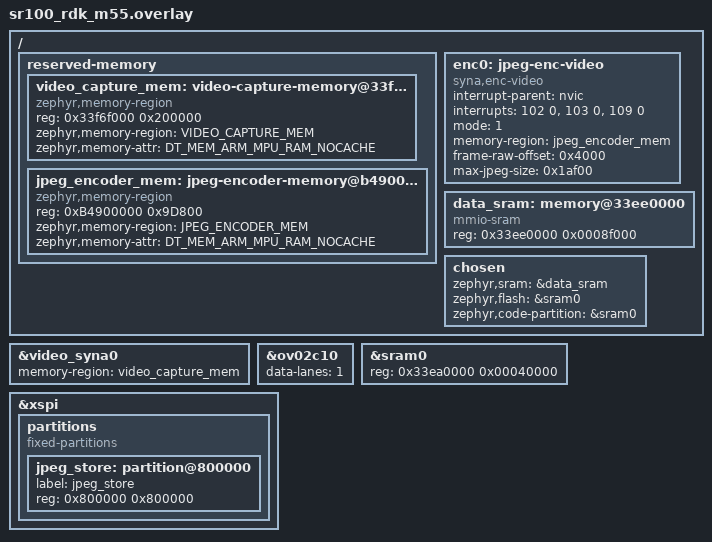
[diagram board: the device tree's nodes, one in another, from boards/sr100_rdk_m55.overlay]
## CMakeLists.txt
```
# Copyright (c) 2026 Synaptics Incorporated
# SPDX-License-Identifier: Apache-2.0

cmake_minimum_required(VERSION 3.20.0)

find_package(Zephyr REQUIRED HINTS $ENV{ZEPHYR_BASE})
project(mipi_capture_to_enc)

if(CONFIG_USB_TRANSPORT_CDC_ACM OR CONFIG_USB_TRANSPORT_UVC)
  include(${ZEPHYR_BASE}/samples/subsys/usb/common/common.cmake)
endif()

target_sources(app PRIVATE src/main.c)

if(CONFIG_USB_TRANSPORT_CDC_ACM)
  target_sources(app PRIVATE src/usb_cdc_transport.c)
endif()

if(CONFIG_USB_TRANSPORT_UVC)
  target_sources(app PRIVATE src/usb_uvc_transport.c)
endif()
```

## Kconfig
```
# Copyright (c) 2026 Synaptics Incorporated
# SPDX-License-Identifier: Apache-2.0

mainmenu "MIPI Capture-to-Encoder Sample"

source "Kconfig.zephyr"

# Tell the SR100 MIPI driver this app provides its own DT-reserved SHM pool
# (video_capture_mem in the board overlay), so the driver's fallback buffer is not
# compiled in.
config VIDEO_SAMPLE_RES_FHD
	bool
	default y

config STORE_TO_XSPI
	bool "Store encoded quadrants to XSPI"
	default n
	select CRC
	select FLASH
	select FLASH_MAP
	select FLASH_PAGE_LAYOUT
	help
	  When enabled, the sample captures one 1080p frame, encodes all four
	  960x540 quadrants one-by-one, and stores each encoded JPEG into the
	  XSPI flash partition labeled "jpeg_store".
	  This partition is optional for USB-only runs (CDC streaming without XSPI).

config USB_TRANSPORT_CDC_ACM
	bool "Enable USB CDC ACM transport"
	default n
	select USB_DEVICE_STACK_NEXT
	select USBD_CDC_ACM_CLASS
	select CRC
	select SERIAL
	select UART_LINE_CTRL
	select UART_INTERRUPT_DRIVEN
	help
	  Enable sending the encoded JPEGs to the host over USB CDC ACM.
	  The device enumerates as a CDC-ACM UART and sends a small binary header
	  followed by the JPEG payload for each quadrant.

config USB_TRANSPORT_UVC
	bool "Enable USB video (UVC) transport"
	default n
	select USB_DEVICE_STACK_NEXT
	select USBD_VIDEO_CLASS
	help
	  Enable streaming the encoded quadrant JPEGs to the host as a USB
	  Video Class (UVC) MJPEG stream.

if USB_TRANSPORT_CDC_ACM || USB_TRANSPORT_UVC
	source "samples/subsys/usb/common/Kconfig.sample_usbd"

config SAMPLE_USBD_PRODUCT
	default "Syna_USB"

config SAMPLE_USBD_PID
	default 0x0008
endif
```

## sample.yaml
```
sample:
  name: mipi_capture_to_enc

tests:
  sample.video.mipi_capture_to_enc:
    tags:
      - video
      - camera
      - jpeg
      - mipi
    integration_platforms:
      - sr100_rdk/sr100/m55

  sample.video.mipi_capture_to_enc.cdc:
    tags:
      - video
      - usb
    integration_platforms:
      - sr100_rdk/sr100/m55
    extra_conf_files:
      - prj_cdc.conf
```

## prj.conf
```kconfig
CONFIG_PRINTK=y
CONFIG_CONSOLE=y
CONFIG_UART_CONSOLE=y
CONFIG_STDOUT_CONSOLE=y

CONFIG_LOG=y
CONFIG_LOG_DEFAULT_LEVEL=3
 
CONFIG_POLL=y

CONFIG_VIDEO=y
CONFIG_VIDEO_SYNA_MIPI=y
CONFIG_VIDEO_SYNA_ENC=y
CONFIG_VIDEO_INIT_PRIORITY=90
CONFIG_VIDEO_SYNA_MIPI_INIT_PRIORITY=110

CONFIG_FPU=y
CONFIG_MAIN_STACK_SIZE=6144
CONFIG_CMSIS_RTOS_V2=y
CONFIG_THREAD_NAME=y
CONFIG_THREAD_STACK_INFO=y
CONFIG_THREAD_MONITOR=y
CONFIG_INIT_STACKS=y
CONFIG_NUM_PREEMPT_PRIORITIES=56
# XSPI storage is optional (CONFIG_STORE_TO_XSPI)
```

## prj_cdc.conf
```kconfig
#
# USB CDC ACM transport configuration for the mipi_capture_to_enc sample.
#
# Include this config when building with CONFIG_USB_TRANSPORT_CDC_ACM=y, e.g.:
#   -DEXTRA_CONF_FILE=prj_cdc.conf
#

# USB device stack / UDC tuning
CONFIG_USBD_MAX_SPEED_FULL=y
CONFIG_UDC_DRIVER_HIGH_SPEED_SUPPORT_ENABLED=n
CONFIG_USBD_BOS_SUPPORT=n
CONFIG_USBD_VREQ_SUPPORT=n
CONFIG_UDC_BUF_POOL_SIZE=2048
CONFIG_USBD_MAX_UDC_MSG=8
CONFIG_USBD_MSG_SLAB_COUNT=8
CONFIG_USBD_HWINFO_DEVID_LENGTH=8

# USB threads can get tight with logging + DMA; keep some headroom.
CONFIG_USBD_THREAD_STACK_SIZE=2048
CONFIG_UDC_DWC2_STACK_SIZE=2048

# Quiet USB/UDC logs (avoid flooding UART during CDC transfers).
CONFIG_USBD_LOG_LEVEL_ERR=y
CONFIG_UDC_DRIVER_LOG_LEVEL_ERR=y
CONFIG_USBD_CDC_ACM_LOG_LEVEL_ERR=y
```

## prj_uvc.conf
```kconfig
#
# USB video (UVC) transport configuration for the mipi_capture_to_enc sample.
#
# Include this config when building with CONFIG_USB_TRANSPORT_UVC=y, e.g.:
#   -DEXTRA_CONF_FILE=prj_uvc.conf
#

# USB device stack / UDC tuning
CONFIG_USBD_MAX_SPEED_FULL=y
CONFIG_UDC_DRIVER_HIGH_SPEED_SUPPORT_ENABLED=n
CONFIG_USBD_BOS_SUPPORT=n
CONFIG_USBD_VREQ_SUPPORT=n
CONFIG_UDC_BUF_POOL_SIZE=2048
CONFIG_USBD_MAX_UDC_MSG=8
CONFIG_USBD_MSG_SLAB_COUNT=8
CONFIG_USBD_HWINFO_DEVID_LENGTH=8

# USB threads can get tight with logging + DMA; keep some headroom.
CONFIG_USBD_THREAD_STACK_SIZE=2048
CONFIG_UDC_DWC2_STACK_SIZE=2048

# MIPI capture, JPEG encoder output, and UVC TX each need video buffer descriptors.
CONFIG_VIDEO_BUFFER_POOL_NUM_MAX=4
CONFIG_VIDEO_BUFFER_POOL_HEAP_SIZE=262144

# Quiet USB/UDC logs during frame streaming.
CONFIG_USBD_LOG_LEVEL_ERR=y
CONFIG_UDC_DRIVER_LOG_LEVEL_ERR=y
```

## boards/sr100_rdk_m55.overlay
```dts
/*
 * SR100 RDK overlay for the integrated MIPI capture + JPEG encoder sample.
 *
 * Reserves non-cached memory for the MIPI capture DMA target and JPEG encoder
 * working area.
 */

#include <zephyr/dt-bindings/memory-attr/memory-attr-arm.h>

/ {
	reserved-memory {
		#address-cells = <1>;
		#size-cells = <1>;
		ranges;

		video_capture_mem: video-capture-memory@33f6f000 {
			compatible = "zephyr,memory-region", "mmio-sram";
			reg = <0x33f6f000 0x200000>; /* 1920x1080 RAW8 frame buffer (0x1FA400 bytes). */
			zephyr,memory-region = "VIDEO_CAPTURE_MEM";
			zephyr,memory-attr = <DT_MEM_ARM_MPU_RAM_NOCACHE>;
		};

		jpeg_encoder_mem: jpeg-encoder-memory@b4900000 {
			compatible = "zephyr,memory-region", "mmio-sram";
			reg = <0xB4900000 0x9D800>; /* Reserved for encoder raw input and JPEG output buffers. */
			zephyr,memory-region = "JPEG_ENCODER_MEM";
			zephyr,memory-attr = <DT_MEM_ARM_MPU_RAM_NOCACHE>;
		};
	};

	enc0: jpeg-enc-video {
		compatible = "syna,enc-video";
		status = "okay";
		interrupt-parent = <&nvic>;

		interrupts = <102 0>, <103 0>, <109 0>;
		interrupt-names = "frame-done", "fmin1-stored", "status";

		mode = <1>; /* Memory-input mode */

		/* JPEG encoder working memory (raw input + JPEG output). */
		memory-region = <&jpeg_encoder_mem>;

		/*
		 * Encoder memory layout (mode=1):
		 * - [0x0000..0x3fff] reserved/unused
		 * - [frame-raw-offset .. frame-raw-offset + 0x7e900) raw input (960x540 RAW8)
		 * - JPEG output region placed after raw input (driver-managed)
		 *
		 * Keep the JPEG output region beyond the end of the raw input region.
		 */
		frame-raw-offset = <0x4000>;
		/* Size hint: must accommodate the largest expected JPEG output frame. */
		max-jpeg-size = <0x1af00>;
	};
};

&video_syna0 {
	/* DMA target memory used by the MIPI capture driver. */
	memory-region = <&video_capture_mem>;
};

&ov02c10 {
	data-lanes = <1>;
};

&sram0 {
	/*
	 * Use SRAM for zephyr,flash and zephyr,code-partition to avoid ITCM overflow.
	 * See `README.rst` for memory-layout details.
	 */
	reg = <0x33ea0000 0x00040000>;
	ranges = <0x0 0x33ea0000 0x00040000>;
};

/ {
	data_sram: memory@33ee0000 {
		compatible = "mmio-sram";
		reg = <0x33ee0000 0x0008f000>;
		#address-cells = <1>;
		#size-cells = <1>;
		ranges = <0x0 0x33ee0000 0x0008f000>;
	};

	chosen {
		zephyr,sram = &data_sram;
		zephyr,flash = &sram0;
		zephyr,code-partition = &sram0;
	};
};

&xspi {
	partitions {
		compatible = "fixed-partitions";
		#address-cells = <1>;
		#size-cells = <1>;

		jpeg_store: partition@800000 {
			label = "jpeg_store";
			reg = <0x800000 0x800000>;
		};
	};
};
```

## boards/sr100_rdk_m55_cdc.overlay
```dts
/*
 * Enable USB CDC ACM UART node for the mipi_capture_to_enc sample.
 *
 * Keep this separate so non-USB builds don't enumerate extra CDC interfaces.
 */

&zephyr_udc0 {
	cdc_acm_uart0: cdc_acm_uart0 {
		compatible = "zephyr,cdc-acm-uart";
		label = "Syna CDC ACM";
	};
};
```

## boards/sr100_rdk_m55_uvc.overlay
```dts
/*
 * Enable USB Video class node for the mipi_capture_to_enc sample.
 */

/ {
	uvc: uvc {
		compatible = "zephyr,uvc-device";
	};
};
```

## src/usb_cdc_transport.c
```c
/*
 * Copyright (c) 2026 Synaptics Incorporated
 *
 * SPDX-License-Identifier: Apache-2.0
 */

#include <errno.h>
#include <stddef.h>
#include <stdint.h>
#include <string.h>

#include <zephyr/device.h>
#include <zephyr/drivers/uart.h>
#include <zephyr/kernel.h>
#include <zephyr/sys/byteorder.h>
#include <zephyr/sys/crc.h>
#include <zephyr/sys/time_units.h>
#include <zephyr/usb/usbd.h>

#include <sample_usbd.h>

#include "usb_cdc_transport.h"

/* Simple framing for host-side parsing. */
#define CDC_STREAM_MAGIC UINT32_C(0x51425553) /* "QBUS" */
#define CDC_STREAM_VERSION 1U
#define CDC_STREAM_TX_TIMEOUT K_SECONDS(10)

#define CDC_STREAM_HDR_SIZE 16U

BUILD_ASSERT(CDC_STREAM_HDR_SIZE == (4U + 2U + 1U + 1U + 4U + 4U), "cdc header size mismatch");

static void cdc_irq_handler(const struct device *dev, void *user_data)
{
	struct cdc_transport_ctx *ctx = user_data;

	if ((dev == NULL) || (ctx == NULL)) {
		return;
	}

	while (uart_irq_update(dev) && uart_irq_is_pending(dev)) {
		if (uart_irq_tx_ready(dev)) {
			if (ctx->tx_remaining == 0U) {
				uart_irq_tx_disable(dev);
				k_sem_give(&ctx->tx_done_sem);
				continue;
			}

			int wrote = uart_fifo_fill(dev, ctx->tx_ptr, ctx->tx_remaining);

			if (wrote > 0) {
				ctx->tx_ptr += (size_t)wrote;
				ctx->tx_remaining -= (size_t)wrote;
			} else {
				/* Nothing accepted right now; exit ISR loop. */
				break;
			}
		} else {
			/* No TX work; exit ISR loop. */
			break;
		}
	}
}

static int cdc_send_blocking(struct cdc_transport_ctx *ctx, const uint8_t *data, size_t len)
{
	unsigned int key;

	if ((ctx == NULL) || (ctx->cdc_dev == NULL) || (data == NULL) || (len == 0U)) {
		return -EINVAL;
	}

	/* Ensure the ISR cannot observe partially-updated tx_* state. */
	key = irq_lock();
	uart_irq_tx_disable(ctx->cdc_dev);

	ctx->tx_ptr = data;
	ctx->tx_remaining = len;
	irq_unlock(key);

	k_sem_reset(&ctx->tx_done_sem);

	/* Start TX; ISR will drain the buffer and signal completion. */
	uart_irq_tx_enable(ctx->cdc_dev);
	int ret = k_sem_take(&ctx->tx_done_sem, CDC_STREAM_TX_TIMEOUT);
	if (ret != 0) {
		uart_irq_tx_disable(ctx->cdc_dev);
		ctx->tx_ptr = NULL;
		ctx->tx_remaining = 0U;
	}
	return ret;
}

int cdc_transport_init(struct cdc_transport_ctx *ctx)
{
	int ret;

	if (ctx == NULL) {
		return -EINVAL;
	}

	if (ctx->usbd_ctx != NULL) {
		return 0;
	}

	k_sem_init(&ctx->tx_done_sem, 0, 1);

	/*
	 * Use a polling-based DTR wait to avoid global state in the USBD message
	 * callback path (sample_usbd_init_device() does not provide a user_data).
	 */
	ctx->usbd_ctx = sample_usbd_init_device(NULL);
	if (ctx->usbd_ctx == NULL) {
		return -ENODEV;
	}

	/* If VBUS detection is not supported, enable right away. */
	if (!usbd_can_detect_vbus(ctx->usbd_ctx)) {
		ret = usbd_enable(ctx->usbd_ctx);
		if (ret != 0) {
			(void)usbd_shutdown(ctx->usbd_ctx);
			ctx->usbd_ctx = NULL;
			return ret;
		}
	}

	ctx->cdc_dev = DEVICE_DT_GET(DT_NODELABEL(cdc_acm_uart0));
	if (!device_is_ready(ctx->cdc_dev)) {
		return -ENODEV;
	}

	ret = uart_irq_callback_user_data_set(ctx->cdc_dev, cdc_irq_handler, ctx);
	if (ret != 0) {
		return ret;
	}
	uart_irq_tx_disable(ctx->cdc_dev);

	return 0;
}

int cdc_transport_wait_dtr(struct cdc_transport_ctx *ctx, k_timeout_t timeout)
{
	uint32_t dtr = 0U;

	if ((ctx == NULL) || (ctx->cdc_dev == NULL)) {
		return -ENODEV;
	}

	if (uart_line_ctrl_get(ctx->cdc_dev, UART_LINE_CTRL_DTR, &dtr) == 0 && dtr != 0U) {
		return 0;
	}

	if (timeout.ticks == K_NO_WAIT.ticks) {
		return -EAGAIN;
	}

	if (timeout.ticks == K_FOREVER.ticks) {
		while (true) {
			k_sleep(K_MSEC(20));
			if (uart_line_ctrl_get(ctx->cdc_dev, UART_LINE_CTRL_DTR, &dtr) == 0 &&
			    dtr != 0U) {
				return 0;
			}
		}
	}

	int64_t deadline_ms = (int64_t)k_uptime_get() + (int64_t)k_ticks_to_ms_floor64(timeout.ticks);

	while ((int64_t)k_uptime_get() < deadline_ms) {
		k_sleep(K_MSEC(20));
		if (uart_line_ctrl_get(ctx->cdc_dev, UART_LINE_CTRL_DTR, &dtr) == 0 && dtr != 0U) {
			return 0;
		}
	}

	return -EAGAIN;
}

int cdc_transport_send_jpeg(struct cdc_transport_ctx *ctx, uint16_t image_id,
			    const uint8_t *jpeg, size_t jpeg_len)
{
	uint8_t hdr[CDC_STREAM_HDR_SIZE];
	uint32_t dtr = 0U;
	int ret;

	if ((ctx == NULL) || (jpeg == NULL) || (jpeg_len == 0U)) {
		return -EINVAL;
	}

	if (image_id > UINT8_MAX) {
		return -EINVAL;
	}

	if (jpeg_len > UINT32_MAX) {
		return -EOVERFLOW;
	}

	/* Avoid long TX timeouts when the host hasn't asserted DTR. */
	if ((ctx->cdc_dev == NULL) ||
	    (uart_line_ctrl_get(ctx->cdc_dev, UART_LINE_CTRL_DTR, &dtr) != 0) || (dtr == 0U)) {
		return -ENOTCONN;
	}

	memset(hdr, 0, sizeof(hdr));
	sys_put_le32(CDC_STREAM_MAGIC, &hdr[0]);
	sys_put_le16((uint16_t)CDC_STREAM_VERSION, &hdr[4]);
	hdr[6] = (uint8_t)image_id;
	hdr[7] = 0U; /* flags */
	sys_put_le32((uint32_t)jpeg_len, &hdr[8]);
	sys_put_le32(crc32_ieee(jpeg, jpeg_len), &hdr[12]);

	ret = cdc_send_blocking(ctx, hdr, sizeof(hdr));
	if (ret != 0) {
		return ret;
	}

	return cdc_send_blocking(ctx, jpeg, jpeg_len);
}
```

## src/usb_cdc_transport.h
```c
/*
 * Copyright (c) 2026 Synaptics Incorporated
 *
 * SPDX-License-Identifier: Apache-2.0
 */

#ifndef ZEPHYR_SAMPLES_DRIVERS_VIDEO_MIPI_CAPTURE_TO_ENC_USB_CDC_TRANSPORT_H_
#define ZEPHYR_SAMPLES_DRIVERS_VIDEO_MIPI_CAPTURE_TO_ENC_USB_CDC_TRANSPORT_H_

#include <stddef.h>
#include <stdint.h>

#include <zephyr/device.h>
#include <zephyr/kernel.h>

struct usbd_context;

struct cdc_transport_ctx {
	struct usbd_context *usbd_ctx;
	const struct device *cdc_dev;
	struct k_sem tx_done_sem;
	const uint8_t *tx_ptr;
	size_t tx_remaining;
};

int cdc_transport_init(struct cdc_transport_ctx *ctx);
int cdc_transport_wait_dtr(struct cdc_transport_ctx *ctx, k_timeout_t timeout);
int cdc_transport_send_jpeg(struct cdc_transport_ctx *ctx, uint16_t image_id,
			    const uint8_t *jpeg, size_t jpeg_len);

#endif /* ZEPHYR_SAMPLES_DRIVERS_VIDEO_MIPI_CAPTURE_TO_ENC_USB_CDC_TRANSPORT_H_ */
```

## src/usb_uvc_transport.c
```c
/*
 * Copyright (c) 2026 Synaptics Incorporated
 *
 * SPDX-License-Identifier: Apache-2.0
 */

#include <errno.h>
#include <stddef.h>
#include <stdint.h>
#include <string.h>

#include <zephyr/cache.h>
#include <zephyr/device.h>
#include <zephyr/drivers/video.h>
#include <zephyr/kernel.h>
#include <zephyr/sys/time_units.h>
#include <zephyr/usb/class/usbd_uvc.h>
#include <zephyr/usb/usbd.h>

#include <sample_usbd.h>

#include "usb_uvc_transport.h"

#define QUAD_UVC_MAX_FRAME_SIZE (128U * 1024U)
#define QUAD_UVC_BUF_ALIGN 64U
#define UVC_TX_BUF_COUNT 2U
#define UVC_STREAM_POLL_INTERVAL_MS 1U

BUILD_ASSERT(QUAD_UVC_MAX_FRAME_SIZE <= UINT32_MAX, "UVC frame size must fit in video_buffer.bytesused");

static void uvc_transport_ensure_lock(struct uvc_transport_ctx *ctx)
{
	if (!ctx->lock_initialized) {
		k_mutex_init(&ctx->lock);
		ctx->lock_initialized = true;
	}
}

static void uvc_transport_release_buffers_locked(struct uvc_transport_ctx *ctx)
{
	for (size_t i = 0; i < UVC_TX_BUF_COUNT; i++) {
		if (ctx->tx_vbuf[i] != NULL) {
			(void)video_buffer_release(ctx->tx_vbuf[i]);
			ctx->tx_vbuf[i] = NULL;
		}
		ctx->tx_busy[i] = false;
	}
}

static void uvc_transport_reset_locked(struct uvc_transport_ctx *ctx)
{
	if (ctx->usbd_ctx != NULL) {
		if (ctx->usbd_enabled) {
			(void)usbd_disable(ctx->usbd_ctx);
		}
		(void)usbd_shutdown(ctx->usbd_ctx);
	}

	if (ctx->uvc_dev != NULL) {
		(void)uvc_device_shutdown(ctx->uvc_dev);
	}

	uvc_transport_release_buffers_locked(ctx);
	ctx->usbd_ctx = NULL;
	ctx->uvc_dev = NULL;
	ctx->max_frame_size = 0U;
	ctx->tx_idx = 0U;
	ctx->usbd_enabled = false;
	ctx->initialized = false;
}

static void uvc_transport_reclaim_done(const struct device *uvc_dev, struct uvc_transport_ctx *ctx)
{
	struct video_buffer *done = NULL;

	for (size_t i = 0; i < UVC_TX_BUF_COUNT; i++) {
		if ((video_dequeue(uvc_dev, &done, K_NO_WAIT) != 0) || (done == NULL)) {
			break;
		}

		for (size_t j = 0; j < UVC_TX_BUF_COUNT; j++) {
			if (ctx->tx_vbuf[j] == done) {
				ctx->tx_busy[j] = false;
				break;
			}
		}
	}
}

static int uvc_transport_stream_format_ready(const struct device *uvc_dev)
{
	struct video_format fmt = {
		.type = VIDEO_BUF_TYPE_INPUT,
	};

	if (uvc_dev == NULL) {
		return -ENODEV;
	}

	return video_get_format(uvc_dev, &fmt);
}

static int64_t uvc_transport_timeout_ms(k_timeout_t timeout)
{
	int64_t timeout_ms = (int64_t)k_ticks_to_ms_ceil64(timeout.ticks);

	return MAX(timeout_ms, 1);
}

int uvc_transport_init(struct uvc_transport_ctx *ctx, const struct device *video_ctrl_dev,
		       uint32_t width, uint32_t height, uint32_t max_frame_size)
{
	struct video_format fmt = {
		.type = VIDEO_BUF_TYPE_INPUT,
		.pixelformat = VIDEO_PIX_FMT_JPEG,
		.width = width,
		.height = height,
		.size = max_frame_size,
	};
	int ret;

	if ((ctx == NULL) || (video_ctrl_dev == NULL) || (max_frame_size == 0U)) {
		return -EINVAL;
	}

	if (!device_is_ready(video_ctrl_dev)) {
		return -ENODEV;
	}

	uvc_transport_ensure_lock(ctx);
	k_mutex_lock(&ctx->lock, K_FOREVER);

	if (ctx->initialized) {
		k_mutex_unlock(&ctx->lock);
		return 0;
	}

	if (max_frame_size > QUAD_UVC_MAX_FRAME_SIZE) {
		k_mutex_unlock(&ctx->lock);
		return -ENOMEM;
	}

	ctx->uvc_dev = DEVICE_DT_GET(DT_NODELABEL(uvc));
	if (!device_is_ready(ctx->uvc_dev)) {
		k_mutex_unlock(&ctx->lock);
		return -ENODEV;
	}

	uvc_device_init(ctx->uvc_dev, video_ctrl_dev);

	ret = uvc_device_add_format(ctx->uvc_dev, &fmt);
	if (ret != 0) {
		uvc_transport_reset_locked(ctx);
		k_mutex_unlock(&ctx->lock);
		return ret;
	}

	ret = uvc_device_enable(ctx->uvc_dev);
	if (ret != 0) {
		uvc_transport_reset_locked(ctx);
		k_mutex_unlock(&ctx->lock);
		return ret;
	}

	ctx->usbd_ctx = sample_usbd_init_device(NULL);
	if (ctx->usbd_ctx == NULL) {
		uvc_transport_reset_locked(ctx);
		k_mutex_unlock(&ctx->lock);
		return -ENODEV;
	}
	ctx->usbd_enabled = false;

	if (!usbd_can_detect_vbus(ctx->usbd_ctx)) {
		ret = usbd_enable(ctx->usbd_ctx);
		if (ret != 0) {
			uvc_transport_reset_locked(ctx);
			k_mutex_unlock(&ctx->lock);
			return ret;
		}
		ctx->usbd_enabled = true;
	}

	ctx->max_frame_size = max_frame_size;
	ctx->tx_idx = 0U;
	for (size_t i = 0; i < UVC_TX_BUF_COUNT; i++) {
		ctx->tx_vbuf[i] = video_buffer_aligned_alloc(max_frame_size, QUAD_UVC_BUF_ALIGN,
							     K_NO_WAIT);
		if (ctx->tx_vbuf[i] == NULL) {
			uvc_transport_reset_locked(ctx);
			k_mutex_unlock(&ctx->lock);
			return -ENOMEM;
		}
		ctx->tx_vbuf[i]->type = VIDEO_BUF_TYPE_INPUT;
		ctx->tx_busy[i] = false;
	}
	ctx->initialized = true;
	k_mutex_unlock(&ctx->lock);
	return 0;
}

int uvc_transport_wait_stream_ready(struct uvc_transport_ctx *ctx, k_timeout_t timeout)
{
	int ret;

	if ((ctx == NULL) || (ctx->uvc_dev == NULL)) {
		return -ENODEV;
	}

	if (timeout.ticks == K_NO_WAIT.ticks) {
		ret = uvc_transport_stream_format_ready(ctx->uvc_dev);
		return (ret == 0) ? 0 : -EAGAIN;
	}

	if (timeout.ticks == K_FOREVER.ticks) {
		while (true) {
			ret = uvc_transport_stream_format_ready(ctx->uvc_dev);
			if (ret == 0) {
				return 0;
			}
			if (ret != -EAGAIN) {
				return ret;
			}
			k_sleep(K_MSEC(UVC_STREAM_POLL_INTERVAL_MS));
		}
	}

	int64_t deadline_ms = (int64_t)k_uptime_get() + uvc_transport_timeout_ms(timeout);

	while ((int64_t)k_uptime_get() < deadline_ms) {
		ret = uvc_transport_stream_format_ready(ctx->uvc_dev);
		if (ret == 0) {
			return 0;
		}
		if (ret != -EAGAIN) {
			return ret;
		}
		k_sleep(K_MSEC(UVC_STREAM_POLL_INTERVAL_MS));
	}

	return -ETIMEDOUT;
}

int uvc_transport_send_frame(struct uvc_transport_ctx *ctx, const uint8_t *jpeg, size_t jpeg_len)
{
	const struct device *uvc_dev;
	struct video_buffer *vbuf;
	uint8_t slot = UINT8_MAX;
	int ret;

	if ((ctx == NULL) || (ctx->uvc_dev == NULL) || (jpeg == NULL) || (jpeg_len == 0U)) {
		return -EINVAL;
	}

	if (jpeg_len > UINT32_MAX) {
		return -EOVERFLOW;
	}

	if ((ctx->max_frame_size == 0U) || (jpeg_len > (size_t)ctx->max_frame_size)) {
		return -ENOMEM;
	}

	k_mutex_lock(&ctx->lock, K_FOREVER);

	uvc_dev = ctx->uvc_dev;
	ret = uvc_transport_stream_format_ready(uvc_dev);
	if (ret != 0) {
		k_mutex_unlock(&ctx->lock);
		return (ret == -EAGAIN) ? -ENOTCONN : ret;
	}

	uvc_transport_reclaim_done(uvc_dev, ctx);

	for (size_t i = 0; i < UVC_TX_BUF_COUNT; i++) {
		uint8_t candidate = (ctx->tx_idx + i) % UVC_TX_BUF_COUNT;

		if (!ctx->tx_busy[candidate]) {
			slot = candidate;
			break;
		}
	}

	if (slot == UINT8_MAX) {
		k_mutex_unlock(&ctx->lock);
		return -EAGAIN;
	}

	vbuf = ctx->tx_vbuf[slot];
	if (vbuf == NULL) {
		k_mutex_unlock(&ctx->lock);
		return -ENOMEM;
	}

	memcpy(vbuf->buffer, jpeg, jpeg_len);
	(void)sys_cache_data_flush_range(vbuf->buffer, jpeg_len);

	vbuf->type = VIDEO_BUF_TYPE_INPUT;
	vbuf->bytesused = (uint32_t)jpeg_len;
	vbuf->line_offset = 0U;

	ret = video_enqueue(uvc_dev, vbuf);
	if (ret != 0) {
		k_mutex_unlock(&ctx->lock);
		return ret;
	}

	ctx->tx_busy[slot] = true;
	ctx->tx_idx = (slot + 1U) % UVC_TX_BUF_COUNT;
	k_mutex_unlock(&ctx->lock);
	return 0;
}

int uvc_transport_shutdown(struct uvc_transport_ctx *ctx)
{
	int ret;

	if (ctx == NULL) {
		return -EINVAL;
	}

	uvc_transport_ensure_lock(ctx);
	k_mutex_lock(&ctx->lock, K_FOREVER);

	if (!ctx->initialized || (ctx->usbd_ctx == NULL)) {
		uvc_transport_reset_locked(ctx);
		k_mutex_unlock(&ctx->lock);
		return 0;
	}

	if (ctx->uvc_dev != NULL) {
		struct video_buffer *done = NULL;

		(void)video_stream_stop(ctx->uvc_dev, VIDEO_BUF_TYPE_INPUT);

		for (size_t i = 0; i < UVC_TX_BUF_COUNT; i++) {
			if ((video_dequeue(ctx->uvc_dev, &done, K_NO_WAIT) != 0) || (done == NULL)) {
				break;
			}
		}
	}

	ret = ctx->usbd_enabled ? usbd_disable(ctx->usbd_ctx) : 0;
	if (usbd_shutdown(ctx->usbd_ctx) != 0 && ret == 0) {
		ret = -EIO;
	}
	(void)uvc_device_shutdown(ctx->uvc_dev);
	uvc_transport_release_buffers_locked(ctx);
	ctx->usbd_ctx = NULL;
	ctx->uvc_dev = NULL;
	ctx->max_frame_size = 0U;
	ctx->tx_idx = 0U;
	ctx->usbd_enabled = false;
	ctx->initialized = false;
	k_mutex_unlock(&ctx->lock);
	return ret;
}
```

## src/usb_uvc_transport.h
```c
/*
 * Copyright (c) 2026 Synaptics Incorporated
 *
 * SPDX-License-Identifier: Apache-2.0
 */

#ifndef ZEPHYR_SAMPLES_DRIVERS_VIDEO_MIPI_CAPTURE_TO_ENC_USB_UVC_TRANSPORT_H_
#define ZEPHYR_SAMPLES_DRIVERS_VIDEO_MIPI_CAPTURE_TO_ENC_USB_UVC_TRANSPORT_H_

#include <stddef.h>
#include <stdint.h>

#include <zephyr/device.h>
#include <zephyr/drivers/video.h>
#include <zephyr/kernel.h>

struct usbd_context;

struct uvc_transport_ctx {
	struct usbd_context *usbd_ctx;
	const struct device *uvc_dev;
	uint32_t max_frame_size;
	struct video_buffer *tx_vbuf[2];
	bool tx_busy[2];
	uint8_t tx_idx;
	bool usbd_enabled;
	bool initialized;
	bool lock_initialized;
	struct k_mutex lock;
};

int uvc_transport_init(struct uvc_transport_ctx *ctx, const struct device *video_ctrl_dev,
		       uint32_t width, uint32_t height, uint32_t max_frame_size);
int uvc_transport_wait_stream_ready(struct uvc_transport_ctx *ctx, k_timeout_t timeout);
int uvc_transport_send_frame(struct uvc_transport_ctx *ctx, const uint8_t *jpeg, size_t jpeg_len);
int uvc_transport_shutdown(struct uvc_transport_ctx *ctx);

#endif /* ZEPHYR_SAMPLES_DRIVERS_VIDEO_MIPI_CAPTURE_TO_ENC_USB_UVC_TRANSPORT_H_ */
```
